# M3351 register map
File version: 1.0
Registers are 32-bit, read-write, reset 0x0 unless marked. A register's access mark holds for its fields unless they carry their own. Offsets are from the block's base; [hi:lo] are bit positions; 'fields as' and 'values as' point back to an identical list.

## CANFD0 — CANFD Register Map
Base 0x40020000
Same registers: CANFD1 0x40024000, CANFD0_NS 0x50020000, CANFD1_NS 0x50024000
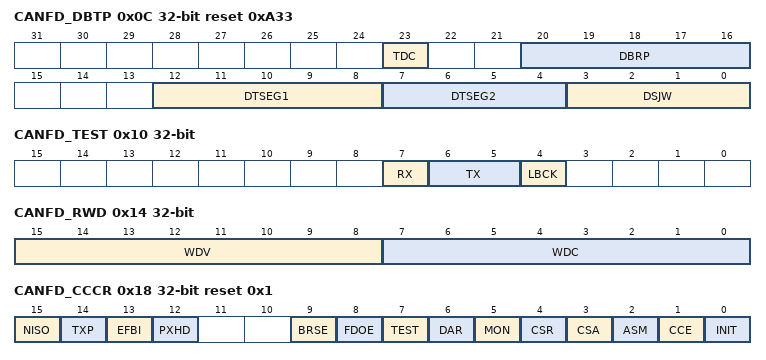
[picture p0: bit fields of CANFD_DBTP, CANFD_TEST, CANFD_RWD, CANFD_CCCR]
0x0C CANFD_DBTP reset 0xA33 — Data Bit Timing Prescaler Register (P*)
  [23] TDC — Transmitter Delay Compensation
    0=Transmitter Delay Compensation disabled; 1=Transmitter Delay Compensation enabled
  [20:16] DBRP — Data Bit Rate Prescaler
  [12:8] DTSEG1 — Data time segment before sample point
  [7:4] DTSEG2 — Data time segment after sample point
  [3:0] DSJW — Data Re-Synchronization Jump Width
0x10 CANFD_TEST — Test Register (P*)
  [7] RX — Receive Pin. Monitors the actual value of pin CANx_RXD
    0=The CAN bus is dominant (CANx_RXD = 0); 1=The CAN bus is recessive (CANx_RXD = 1)
  [6:5] TX — Control of Transmit Pin
    0=Reset value, CANx_TXD controlled by the CAN Core, updated at the end of the CAN bit time; 1=Sample Point can be monitored at pin CANx_TXD; 2=Dominant (0) level at pin CANx_TXD; 3=Recessive (1) level at pin CANx_TXD
  [4] LBCK — Loop Back Mode
    0=Reset value, Loop Back Mode disabled; 1=Loop Back Mode enabled (refer to TEST Mode in Operation Mode section)
0x14 CANFD_RWD — RAM Watchdog (P*)
  [15:8] WDV — Watchdog Value. Actual Message RAM Watchdog Counter Value.
  [7:0] WDC — Watchdog Configuration. Start value of the Message RAM Watchdog Counter. With the reset value of 00 the counter is disabled.
0x18 CANFD_CCCR reset 0x1 — CC Control Register (Pp*)
  [15] NISO — Non ISO Operation. If this bit is set, the CAN FD controller uses the CAN FD frame format as specified by the Bosch CAN FD Specification V1.0.
    0=CAN FD frame format according to ISO 11898-1:2015; 1=CAN FD frame format according to Bosch CAN FD Specification V1.0
  [14] TXP — Transmit Pause. If this bit is set, the CAN FD controller pauses for two CAN bit times before starting the next transmission after itself has successfully transmitted a frame (refer to Tx Handling section).
    0=Transmit pause disabled; 1=Transmit pause enabled
  [13] EFBI — Edge Filtering during Bus Integration
    0=Edge filtering disabled; 1=Two consecutive dominant tq required to detect an edge for hard synchronization
  [12] PXHD — Protocol Exception Handling Disable Bit. Note: When protocol exception handling is disabled, the controller will transmit an error frame when it detects a protocol exception condition.
    0=Protocol exception handling enabled; 1=Protocol exception handling disabled
  [9] BRSE — Bit Rate Switch Enable Bit
    0=Bit rate switching for transmissions disabled; 1=Bit rate switching for transmissions enabled
  [8] FDOE — FD Operation Enable Bit
    0=FD operation disabled; 1=FD operation enabled
  [7] TEST — Test Mode Enable Bit
    0=Normal operation, register TEST holds reset values; 1=Test Mode, write access to register TEST enabled
  [6] DAR — Disable Automatic Retransmission
    0=Automatic retransmission of messages not transmitted successfully enabled; 1=Automatic retransmission disabled
  [5] MON — Bus Monitoring Mode. Bit MON can only be set by the Host when both CCE and INIT are set to 1. The bit can be reset by the Host at any time.
    0=Bus Monitoring Mode disabled; 1=Bus Monitoring Mode enabled
  [4] CSR — Clock Stop Request
    0=No clock stop is requested; 1=Clock stop requested. When clock stop is requested, first INIT and then CSA will be set after all pending transfer requests have been completed and the CAN bus reached idle
  [3] CSA — Clock Stop Acknowledge
    0=No clock stop acknowledged; 1=The Controller may be set in power down by stopping AHB clock and CAN Core clock
  [2] ASM — Restricted Operation Mode. Bit ASM can only be set by the Host when both CCE and INIT are set to 1. The bit can be reset by the software at any time. This bit will be set automatically set to 1 when the Tx handler was not able to read data from the message RAM in time. For a description of the Restricted Operation Mode, refer to Restricted Operation Mode.
    0=Normal CAN operation; 1=Restricted Operation Mode active
  [1] CCE — Configuration Change Enable Bit
    0=The CPU has no write access to the protected configuration registers; 1=The CPU has write access to the protected configuration registers (while INIT (CANFD_CCCR[0]) = 1)
  [0] INIT — Initialization. Note: Due to the synchronization mechanism between the two clock domains, there may be a delay until the value written to INIT can be read back. Therefore the programmer has to assure that the previous value written to INIT has been accepted by reading INIT before setting INIT to a new value.
    0=Normal Operation; 1=Initialization is started
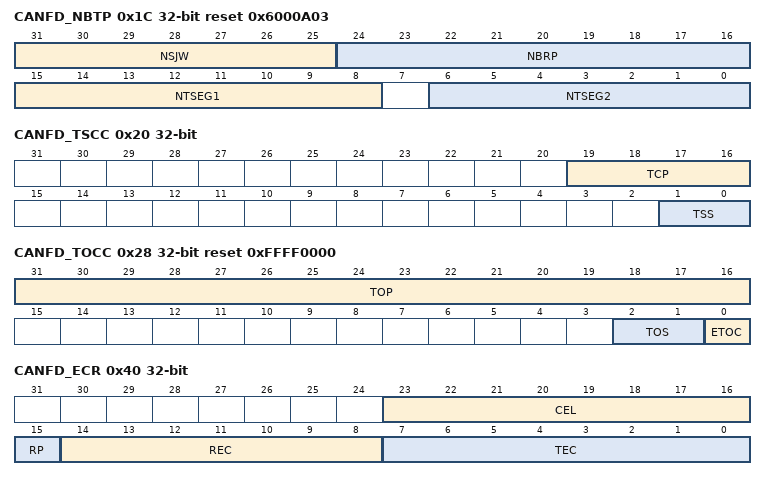
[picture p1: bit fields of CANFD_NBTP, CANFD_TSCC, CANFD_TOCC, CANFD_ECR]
0x1C CANFD_NBTP reset 0x6000A03 — Nominal Bit Timing Prescaler Register (P*)
  [31:25] NSJW — Nominal Re-Synchronization Jump Width
  [24:16] NBRP — Nominal Bit Rate Prescaler. The value by which the oscillator frequency is divided for generating the bit time quanta. The bit time is built up from a multiple of this quanta. Valid values for the Bit Rate Prescaler are 0 to 511. The actual interpretation by the hardware of this value is such that one more than the value programmed here is used
  [15:8] NTSEG1 — Nominal Time Segment before Sample Point
  [6:0] NTSEG2 — Nominal Time Segment after Sample Point. Note: With a CAN Core clock (cclk) of 8 MHz, the reset value of 0x06000A03 configures the controller for a bit rate of 500 kBit/s.
0x20 CANFD_TSCC — Timestamp Counter Configuration (P*)
  [19:16] TCP — Timestamp Counter Prescaler. Configures the timestamp and timeout counters time unit in multiples of CAN bit times [ 1...16 ]. The actual interpretation by the hardware of this value is such that one more than the value programmed here is used.
  [1:0] TSS — Timestamp Select
    0=Timestamp counter value always 0x0000; 1=Timestamp counter value incremented according to TCP; 2=2nd timestamp counter value used (clock source comes from CCLK); 3=Same as 00
0x24 CANFD_TSCV — Timestamp Counter Value (C*)
  [15:0] TSC — Timestamp Counter. Note: A wrap around is a change of the Timestamp Counter value from non-zero to 0 not caused by write access to CANFD_TSCV.
0x28 CANFD_TOCC reset 0xFFFF0000 — Timeout Counter Configuration (P*)
  [31:16] TOP — Timeout Period. Start value of the Timeout Counter (down-counter). Configures the Timeout Period.
  [2:1] TOS — Timeout Select. When operating in Continuous mode, a write to CANFD_TOCV presets the counter to the value configured by TOP (CANFD_TOCC[31:16]) and continues down-counting. When the Timeout Counter is controlled by one of the FIFOs, an empty FIFO presets the counter to the value configured by TOP (CANFD_TOCC[31:16]). Down-counting is started when the first FIFO element is stored.
    0=Continuous operation; 1=Timeout controlled by Tx Event FIFO; 2=Timeout controlled by Rx FIFO 0; 3=Timeout controlled by Rx FIFO 1
  [0] ETOC — Enable Timeout Counter. Note: For use of timeout function with CAN FD, refer to Timeout Counter section6.33.5.3.
    0=Timeout Counter disabled; 1=Timeout Counter enabled
0x2C CANFD_TOCV reset 0xFFFF — Timeout Counter Value (C*)
  [15:0] TOC — Timeout Counter. The filed is decremented in multiples of CAN bit times [ 1...16 ] depending on the configuration of TCP (CANFD_TSCC[19:16]). When decremented to 0, interrupt flag TOO (CANFD_IR[18]) is set and the timeout counter is stopped. Start and reset/restart conditions are configured via TOS (CANFD_TOCC[2:1]).
0x40 CANFD_ECR ro — Error Counter Register (X*)
  [23:16] CEL — CAN Error Logging. The counter is incremented each time when a CAN protocol error causes the 8-bit Transmit Error Counter TEC or the 7-bit Receive Error Counter REC to be incremented. The counter is also incremented when the Bus_Off limit is reached. It is not incremented when only RP is set without changing REC. The increment of CEL follows after the increment of REC or TEC. The counter is reset by read access to CEL. The counter stops at 0xFF; the next increment of TEC or REC sets interrupt flag ELO (CANFD_IR[22]).
  [15] RP — Receive Error Passive
    0=The Receive Error Counter is below the error passive level of 128; 1=The Receive Error Counter has reached the error passive level of 128
  [14:8] REC — Receive Error Counter. Actual state of the Receive Error Counter, values between 0 and 127.
  [7:0] TEC — Transmit Error Counter. Actual state of the Transmit Error Counter, values between 0 and 255. Note: When ASM (CANFD_CCCR[2]) is set, the CAN protocol controller does not increment TEC and REC when a CAN protocol error is detected, but CEL is still incremented.
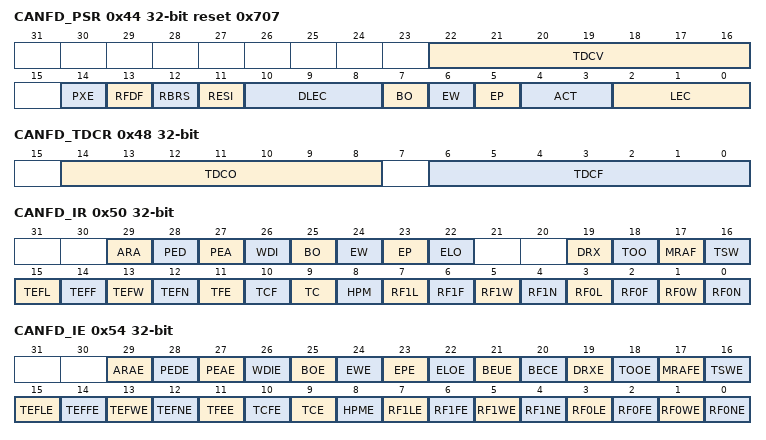
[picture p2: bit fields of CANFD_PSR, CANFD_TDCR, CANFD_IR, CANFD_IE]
0x44 CANFD_PSR ro reset 0x707 — Protocol Status Register (XS*)
  [22:16] TDCV — Transmitter Delay Compensation Value. Position of the secondary sample point, defined by the sum of the measured delay from CANx_TXD to CANx_RXD and TDCO (CANFD_TDCR[14:8]). The SSP position is, in the data phase, the number of minimum time quata (mtq) between the start of the transmitted bit and the secondary sample point. Valid values are 0 to 127 mtq.
  [14] PXE — Protocol Exception Event
    0=No protocol exception event occurred since last read access; 1=Protocol exception event occurred
  [13] RFDF — Received a CAN FD Message. This bit is set independent of acceptance filtering. Note: Byte access: Reading byte 0 will reset RFDF, reading bytes 3/2/1 has no impact.
    0=Since this bit was reset by the CPU, no CAN FD message has been received; 1=Message in CAN FD format with FDF flag set has been received
  [12] RBRS — BRS flag of last received CAN FD Message. This bit is set together with RFDF, independent of acceptance filtering. Note: Byte access: Reading byte 0 will reset RBRS, reading bytes 3/2/1 has no impact.
    0=Last received CAN FD message did not have its BRS flag set; 1=Last received CAN FD message had its BRS flag set
  [11] RESI — ESI flag of last received CAN FD Message. This bit is set together with RFDF, independent of acceptance filtering.
    0=Last received CAN FD message did not have its ESI flag set; 1=Last received CAN FD message had its ESI flag set
  [10:8] DLEC — Data Phase Last Error Code. Type of last error that occurred in the data phase of a CAN FD format frame with its BRS flag set. Coding is the same as for LEC. This field will be cleared to 0 when a CAN FD format frame with its BRS flag set has been transferred (reception or transmission) without error.
  [7] BO — Bus_Off Status
    0=The CAN FD controller is not Bus_Off; 1=The CAN FD controller is in Bus_Off state
  [6] EW — Warning Status
    0=Both error counters are below the Error_Warning limit of 96; 1=At least one of error counter has reached the Error_Warning limit of 96
  [5] EP — Error Passive
    0=The CAN FD controller is in the Error_Active state. It normally takes part in bus communication and sends an active error flag when an error has been detected; 1=The CAN FD controller is in the Error_Passive state
  [4:3] ACT — Activity. Monitors the communication state of the CAN module.
    0=Synchronizing - node is synchronizing on CAN communication; 1=Idle - node is neither receiver nor transmitter; 2=Receiver - node is operating as receiver; 3=Transmitter - node is operating as transmitter
  [2:0] LEC — Last Error Code. The LEC indicates the type of the last error to occur on the CAN bus. This field will be cleared to 0 when a message has been transferred (reception or transmission) without error.
    0=No Error: No error occurred since LEC has been reset by successful reception or transmission; 1=Stuff Error: More than 5 equal bits in a sequence have occurred in a part of a received message where this is not allowed; 2=Form Error: A fixed format part of a received frame has the wrong format; 3=AckError: The message transmitted by the CANFD CONTROLLER was not acknowledged by another node; 4=Bit1Error: During the transmission of a message (with the exception of the arbitration field), the device wanted to send a recessive level (bit of logical value 1), but the monitored bus value was dominant; 5=Bit0Error : During the transmission of a message (or acknowledge bit, or active error flag, or overload flag), the device wanted to send a dominant level (data or identifier bit logical value 0), but the monitored bus value was recessive. During Bus_Off recovery this status is set each time a sequence of 11 recessive bits has been monitored. This enables the CPU to monitor the proceeding of the Bus_Off recovery sequence (indicating the bus is not stuck at dominant or continuously disturbed); 6=CRCError: The CRC check sum of a received message was incorrect. The CRC of an incoming message does not match with the CRC calculated from the received data; 7=NoChange: Any read access to the Protocol Status Register re-initializes the LEC to 7.When the LEC shows the value 7, no CAN bus event was detected since the last CPU read access to the Protocol Status Register
0x48 CANFD_TDCR — Transmitter Delay Compensation Register (P*)
  [14:8] TDCO — Transmitter Delay Compensation SSP Offset. Offset value defining the distance between the measured delay from CANx_TXD to CANx_RXD and the secondary sample point. Valid values are 0 to 127 mtq.
  [6:0] TDCF — Transmitter Delay Compensation Filter Window Length. Defines the minimum value for the SSP position, dominant edges on CANx_RXD that would result in an earlier SSP position are ignored for transmitter delay measurement. The feature is enabled when TDCF is configured to a value greater than TDCO. Valid values are 0 to 127 mtq.
0x50 CANFD_IR — Interrupt Register
  [29] ARA — Access to Reserved Address
    0=No access to reserved address occurred; 1=Access to reserved address occurred
  [28] PED — Protocol Error in Data Phase. Note: Data bit time is used.
    0=No protocol error in data phase; 1=Protocol error in data phase detected (DLEC (CANFD_PSR[10:8]) no equal 0 or 7)
  [27] PEA — Protocol Error in Arbitration Phase. Note: Nominal bit time is used.
    0=No protocol error in arbitration phase; 1=Protocol error in arbitration phase detected (LEC (CANFD_PSR[2:0]) no equal 0 or 7)
  [26] WDI — Watchdog Interrupt
    0=No Message RAM Watchdog event occurred; 1=Message RAM Watchdog event due to missing READY
  [25] BO — Bus_Off Status
    0=Bus_Off status unchanged; 1=Bus_Off status changed
  [24] EW — Warning Status
    0=Error_Warning status unchanged; 1=Error_Warning status changed
  [23] EP — Error Passive
    0=Error_Passive status unchanged; 1=Error_Passive status changed
  [22] ELO — Error Logging Overflow
    0=CAN Error Logging Counter did not overflow; 1=Overflow of CAN Error Logging Counter occurred
  [19] DRX — Message stored to Dedicated Rx Buffer. The flag is set whenever a received message has been stored into a dedicated Rx Buffer.
    0=No Rx Buffer updated; 1=At least one received message stored into an Rx Buffer
  [18] TOO — Timeout Occurred
    0=No timeout; 1=Timeout reached
  [17] MRAF — Message RAM Access Failure. The flag is set, when the Rx Handler - Has not completed acceptance filtering or storage of an accepted message until the arbitration field of the following message has been received. In this case acceptance filtering or message storage is aborted and the Rx Handler starts processing of the following message. - Was not able to write a message to the Message RAM. In this case message storage is aborted. In both cases the FIFO put index is not updated resp. the New Data flag for a dedicated Rx Buffer is not set, a partly stored message is overwritten when the next message is stored to this location. The flag is also set when the Tx Handler was not able to read a message from the Message RAM in time. In this case message transmission is aborted. In case of a Tx Handler access failure the CAN FD controller is switched into Restricted Operation Mode (refer to Restricted Operation Mode). To leave Restricted Operation Mode, the Host CPU has to reset ASM (CANFD_CCCR[2]).
    0=No Message RAM access failure occurred; 1=Message RAM access failure occurred
  [16] TSW — Timestamp Wraparound
    0=No timestamp counter wrap-around; 1=Timestamp counter wrapped around
  [15] TEFL — Tx Event FIFO Element Lost
    0=No Tx Event FIFO element lost; 1=Tx Event FIFO element lost, also set after write attempt to Tx Event FIFO of size zero
  [14] TEFF — Tx Event FIFO Full
    0=Tx Event FIFO not full; 1=Tx Event FIFO full
  [13] TEFW — Tx Event FIFO Watermark Reached
    0=Tx Event FIFO fill level below watermark; 1=Tx Event FIFO fill level reached watermark
  [12] TEFN — Tx Event FIFO New Entry
    0=Tx Event FIFO unchanged; 1=Tx Handler wrote Tx Event FIFO element
  [11] TFE — Tx FIFO Empty
    0=Tx FIFO non-empty; 1=Tx FIFO empty
  [10] TCF — Transmission Cancellation Finished
    0=No transmission cancellation finished; 1=Transmission cancellation finished
  [9] TC — Transmission Completed
    0=No transmission completed; 1=Transmission completed
  [8] HPM — High Priority Message
    0=No high priority message received; 1=High priority message received
  [7] RF1L — Rx FIFO 1 Message Lost
    0=No Rx FIFO 1 message lost; 1=Rx FIFO 1 message lost, also set after write attempt to Rx FIFO 1 of size zero
  [6] RF1F — Rx FIFO 1 Full
    0=Rx FIFO 1 not full; 1=Rx FIFO 1 full
  [5] RF1W — Rx FIFO 1 Watermark Reached
    0=Rx FIFO 1 fill level below watermark; 1=Rx FIFO 1 fill level reached watermark
  [4] RF1N — Rx FIFO 1 New Message
    0=No new message written to Rx FIFO 1; 1=New message written to Rx FIFO 1
  [3] RF0L — Rx FIFO 0 Message Lost
    0=No Rx FIFO 0 message lost; 1=Rx FIFO 0 message lost, also set after write attempt to Rx FIFO 0 of size zero
  [2] RF0F — Rx FIFO 0 Full
    0=Rx FIFO 0 not full; 1=Rx FIFO 0 full
  [1] RF0W — Rx FIFO 0 Watermark Reached
    0=Rx FIFO 0 fill level below watermark; 1=Rx FIFO 0 fill level reached watermark
  [0] RF0N — Rx FIFO 0 New Message
    0=No new message written to Rx FIFO 0; 1=New message written to Rx FIFO 0
0x54 CANFD_IE — Interrupt Enable
  [all] fields
    0=Interrupt disabled; 1=Interrupt enabled
  [29] ARAE — Access to Reserved Address Enable Bit
  [28] PEDE — Protocol Error in Data Phase Enable Bit
  [27] PEAE — Protocol Error in Arbitration Phase Enable Bit
  [26] WDIE — Watchdog Interrupt Enable Bit
  [25] BOE — Bus_Off Status Interrupt Enable Bit
  [24] EWE — Warning Status Interrupt Enable Bit
  [23] EPE — Error Passive Interrupt Enable Bit
  [22] ELOE — Error Logging Overflow Interrupt Enable Bit
  [21] BEUE — Bit Error Uncorrected Interrupt Enable Bit
  [20] BECE — Bit Error Corrected Interrupt Enable Bit
  [19] DRXE — Message stored to Dedicated Rx Buffer Interrupt Enable Bit
  [18] TOOE — Timeout Occurred Interrupt Enable Bit
  [17] MRAFE — Message RAM Access Failure Interrupt Enable Bit
  [16] TSWE — Timestamp Wraparound Interrupt Enable Bit
  [15] TEFLE — Tx Event FIFO Event Lost Interrupt Enable Bit
  [14] TEFFE — Tx Event FIFO Full Interrupt Enable Bit
  [13] TEFWE — Tx Event FIFO Watermark Reached Interrupt Enable Bit
  [12] TEFNE — Tx Event FIFO New Entry Interrupt Enable Bit
  [11] TFEE — Tx FIFO Empty Interrupt Enable Bit
  [10] TCFE — Transmission Cancellation Finished Interrupt Enable Bit
  [9] TCE — Transmission Completed Interrupt Enable Bit
  [8] HPME — High Priority Message Interrupt Enable Bit
  [7] RF1LE — Rx FIFO 1 Message Lost Interrupt Enable Bit
  [6] RF1FE — Rx FIFO 1 Full Interrupt Enable Bit
  [5] RF1WE — Rx FIFO 1 Watermark Reached Interrupt Enable Bit
  [4] RF1NE — Rx FIFO 1 New Message Interrupt Enable Bit
  [3] RF0LE — Rx FIFO 0 Message Lost Interrupt Enable Bit
  [2] RF0FE — Rx FIFO 0 Full Interrupt Enable Bit
  [1] RF0WE — Rx FIFO 0 Watermark Reached Interrupt Enable Bit
  [0] RF0NE — Rx FIFO 0 New Message Interrupt Enable Bit
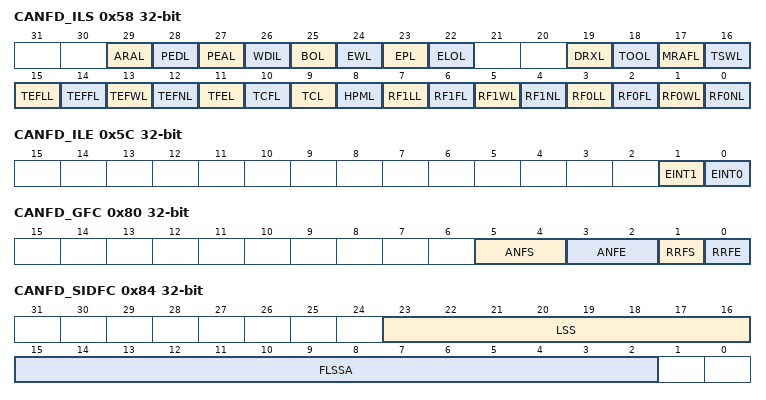
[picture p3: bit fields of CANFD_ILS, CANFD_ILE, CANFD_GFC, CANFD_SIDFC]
0x58 CANFD_ILS — Interrupt Line Select
  [all] fields
    0=Interrupt assigned to CAN interrupt line 0; 1=Interrupt assigned to CAN interrupt line 1
  [29] ARAL — Access to Reserved Address Line
  [28] PEDL — Protocol Error in Data Phase Line
  [27] PEAL — Protocol Error in Arbitration Phase Line
  [26] WDIL — Watchdog Interrupt Line
  [25] BOL — Bus_Off Status Interrupt Line
  [24] EWL — Warning Status Interrupt Line
  [23] EPL — Error Passive Interrupt Line
  [22] ELOL — Error Logging Overflow Interrupt Line
  [19] DRXL — Message stored to Dedicated Rx Buffer Interrupt Line
  [18] TOOL — Timeout Occurred Interrupt Line
  [17] MRAFL — Message RAM Access Failure Interrupt Line
  [16] TSWL — Timestamp Wraparound Interrupt Line
  [15] TEFLL — Tx Event FIFO Event Lost Interrupt Line
  [14] TEFFL — Tx Event FIFO Full Interrupt Line
  [13] TEFWL — Tx Event FIFO Watermark Reached Interrupt Line
  [12] TEFNL — Tx Event FIFO New Entry Interrupt Line
  [11] TFEL — Tx FIFO Empty Interrupt Line
  [10] TCFL — Transmission Cancellation Finished Interrupt Line
  [9] TCL — Transmission Completed Interrupt Line
  [8] HPML — High Priority Message Interrupt Line
  [7] RF1LL — Rx FIFO 1 Message Lost Interrupt Line
  [6] RF1FL — Rx FIFO 1 Full Interrupt Line
  [5] RF1WL — Rx FIFO 1 Watermark Reached Interrupt Line
  [4] RF1NL — Rx FIFO 1 New Message Interrupt Line
  [3] RF0LL — Rx FIFO 0 Message Lost Interrupt Line
  [2] RF0FL — Rx FIFO 0 Full Interrupt Line
  [1] RF0WL — Rx FIFO 0 Watermark Reached Interrupt Line
  [0] RF0NL — Rx FIFO 0 New Message Interrupt Line
0x5C CANFD_ILE — Interrupt Line Enable
  [1] EINT1 — Enable Interrupt Line 1
    0=Interrupt line canfd_int1 disabled; 1=Interrupt line canfd_int1 enabled
  [0] EINT0 — Enable Interrupt Line 0
    0=Interrupt line canfd_int0 disabled; 1=Interrupt line canfd_int0 enabled
0x80 CANFD_GFC — Global Filter Configuration (P*)
  [5:4] ANFS — Accept Non-matching Frames Standard. Defines how received messages with 11-bit IDs that do not match any element of the filter list are treated.
    0=Accept in Rx FIFO 0; 1=Accept in Rx FIFO 1; 2=Reject; 3=Reject
  [3:2] ANFE — Accept Non-matching Frames Extended. Defines how received messages with 29-bit IDs that do not match any element of the filter list are treated.
    values as ANFS
  [1] RRFS — Reject Remote Frames Standard
    0=Filter remote frames with 11-bit standard IDs; 1=Reject all remote frames with 11-bit standard IDs
  [0] RRFE — Reject Remote Frames Extended
    0=Filter remote frames with 29-bit extended IDs; 1=Reject all remote frames with 29-bit extended IDs
0x84 CANFD_SIDFC — Standard ID Filter Configuration (P*)
  [23:16] LSS — List Size Standard
    0=No standard Message ID filter
  [15:2] FLSSA — Filter List Standard Start Address. Start address of standard Message ID filter list (32-bit word address, refer to Figure 6.3311).
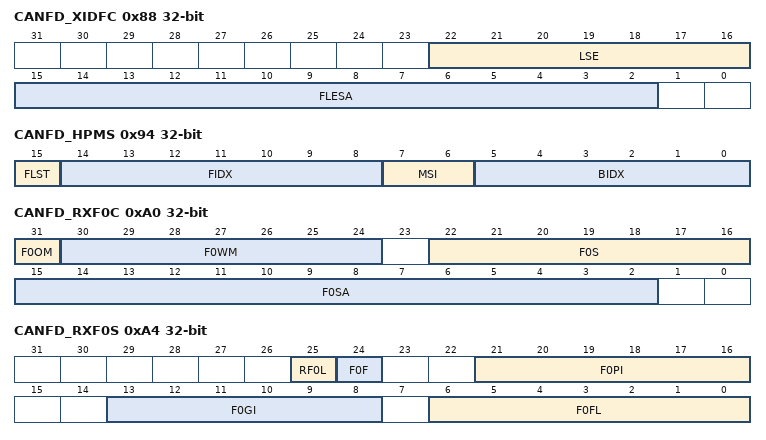
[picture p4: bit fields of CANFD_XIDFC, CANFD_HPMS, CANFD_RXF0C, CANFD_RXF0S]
0x88 CANFD_XIDFC — Extended ID Filter Configuration (P*)
  [22:16] LSE — List Size Extended
    0=No extended Message ID filter
  [15:2] FLESA — Filter List Extended Start Address. Start address of extended Message ID filter list (32-bit word address, refer to Figure 6.3311).
0x90 CANFD_XIDAM reset 0x1FFFFFFF — Extended ID AND Mask (P*)
  [28:0] EIDM — Extended ID Mask. For acceptance filtering of extended frames, the Extended ID AND Mask is ANDed with the Message ID of a received frame. Intended for masking of 29-bit IDs in SAE J1939. With the reset value of all bits set to one the mask is not active.
0x94 CANFD_HPMS ro — High Priority Message Status
  [15] FLST — Filter List. Indicates the filter list of the matching filter element.
    0=Standard Filter List; 1=Extended Filter List
  [14:8] FIDX — Filter Index. Index of matching filter element. Range is 0 to LSS (CANFD_SIDFC[23:16]) - 1 or LSE (CANFD_XIDFC[22:16]) - 1
  [7:6] MSI — Message Storage Indicator
    0=No FIFO selected; 1=FIFO message lost; 2=Message stored in FIFO 0; 3=Message stored in FIFO 1
  [5:0] BIDX — Buffer Index
0x98 CANFD_NDAT1 — New Data 1
  [31:0] NDn — New Data. The register holds the New Data flags of Rx Buffers 0 to 31. The flags are set when the respective Rx Buffer has been updated from a received frame. The flags remain set until the Host clears them. A flag is cleared by writing a 1 to the corresponding bit position. Writing a 0 has no effect. A hard reset will clear the register.
    0=Rx Buffer not updated; 1=Rx Buffer updated from new message
0x9C CANFD_NDAT2 — New Data 2
  [31:0] NDn — New Data. The register holds the New Data flags of Rx Buffers 32 to 63. The flags are set when the respective Rx Buffer has been updated from a received frame. The flags remain set until the Host clears them. A flag is cleared by writing a 1 to the corresponding bit position. Writing a 0 has no effect. A hard reset will clear the register.
    values as CANFD_NDAT1.NDn
0xA0 CANFD_RXF0C — Rx FIFO 0 Configuration (P*)
  [31] F0OM — FIFO 0 Operation Mode. FIFO 0 can be operated in blocking or in overwrite mode (refer to Rx FIFOs).
    0=FIFO 0 blocking mode; 1=FIFO 0 overwrite mode
  [30:24] F0WM — Rx FIFO 0 Watermark
    0=Watermark interrupt disabled
  [22:16] F0S — Rx FIFO 0 Size. The Rx FIFO 0 elements are indexed from 0 to F0S - 1
    0=No Rx FIFO 0
  [15:2] F0SA — Rx FIFO 0 Start Address. Start address of Rx FIFO 0 in Message RAM (32-bit word address).
0xA4 CANFD_RXF0S ro — Rx FIFO 0 Status
  [25] RF0L — Rx FIFO 0 Message Lost
    1=Rx FIFO 0 message lost, also set after write attempt to Rx FIFO 0 of size zero
  [24] F0F — Rx FIFO 0 Full
    0=Rx FIFO 0 not full; 1=Rx FIFO 0 full
  [21:16] F0PI — Rx FIFO 0 Put Index. Rx FIFO 0 write index pointer, range 0 to 63.
  [13:8] F0GI — Rx FIFO 0 Get Index. Rx FIFO 0 read index pointer, range 0 to 63.
  [6:0] F0FL — Rx FIFO 0 Fill Level. Number of elements stored in Rx FIFO 0, range 0 to 64
0xA8 CANFD_RXF0A — Rx FIFO 0 Acknowledge
  [5:0] F0AI — Rx FIFO 0 Acknowledge Index. After the Host has read a message or a sequence of messages from Rx FIFO 0 it has to write the buffer index of the last element read from Rx FIFO 0 to F0AI. This will set the Rx FIFO 0 Get Index F0GI (CANFD_RXF0S[13:8]) to F0AI (CANFD_RXF0A[5:0]) + 1 and update the FIFO 0 Fill Level F0FL (CANFD_RXF0S[6:0]).
0xAC CANFD_RXBC — Rx Buffer Configuration (P*)
  [15:2] RBSA — Rx Buffer Start Address. Configures the start address of the Rx Buffers section in the Message RAM (32-bit word address).
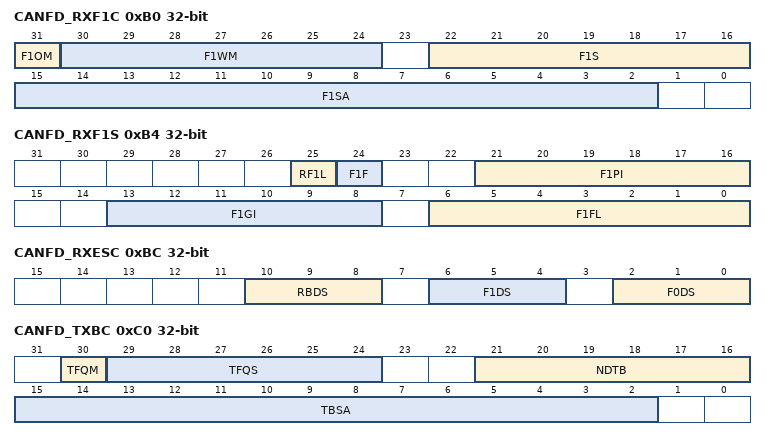
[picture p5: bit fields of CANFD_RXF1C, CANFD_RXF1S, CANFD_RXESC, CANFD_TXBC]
0xB0 CANFD_RXF1C — Rx FIFO 1 Configuration (P*)
  [31] F1OM — FIFO 1 Operation Mode. FIFO 1 can be operated in blocking or in overwrite mode (refer to Rx FIFOs).
    0=FIFO 1 blocking mode; 1=FIFO 1 overwrite mode
  [30:24] F1WM — Rx FIFO 1 Watermark
    0=Watermark interrupt disabled
  [22:16] F1S — Rx FIFO 1 Size. The Rx FIFO 1 elements are indexed from 0 to F1S - 1
    0=No Rx FIFO 1
  [15:2] F1SA — Rx FIFO 1 Start Address. Start address of Rx FIFO 1 in Message RAM (32-bit word address, refer to Figure 6.3311).
0xB4 CANFD_RXF1S ro — Rx FIFO 1 Status
  [25] RF1L — Rx FIFO 1 Message Lost
    1=Rx FIFO 1 message lost, also set after write attempt to Rx FIFO 1 of size zero
  [24] F1F — Rx FIFO 1 Full
    0=Rx FIFO 1 not full; 1=Rx FIFO 1 full
  [21:16] F1PI — Rx FIFO 1 Put Index. Rx FIFO 1 write index pointer, range 0 to 63.
  [13:8] F1GI — Rx FIFO 1 Get Index. Rx FIFO 1 read index pointer, range 0 to 63.
  [6:0] F1FL — Rx FIFO 1 Fill Level. Number of elements stored in Rx FIFO 1, range 0 to 64
0xB8 CANFD_RXF1A — Rx FIFO 1 Acknowledge
  [5:0] F1AI — Rx FIFO 1 Acknowledge Index. After the Host has read a message or a sequence of messages from Rx FIFO 1 it has to write the buffer index of the last element read from Rx FIFO 1 to F1AI. This will set the Rx FIFO 1 Get Index F1GI (CANFD_RXF1S[13:8]) to F1AI (CANFD_RXF1A[5:0]) + 1 and update the FIFO 1 Fill Level F1FL (CANFD_RXF1S[6:0]).
0xBC CANFD_RXESC — Rx Buffer / FIFO Element Size Configuration (P*)
  [all] fields
    0=8 byte data field; 1=12 byte data field; 2=16 byte data field; 3=20 byte data field; 4=24 byte data field; 5=32 byte data field; 6=48 byte data field; 7=64 byte data field
  [10:8] RBDS — Rx Buffer Data Field Size
  [6:4] F1DS — Rx FIFO 1 Data Field Size
  [2:0] F0DS — Rx FIFO 0 Data Field Size. Note: In case the data field size of an accepted CAN frame exceeds the data field size configured for the matching Rx Buffer or Rx FIFO, only the number of bytes as configured by CANFD_RXESC are stored to the Rx Buffer resp. Rx FIFO element. The rest of the frame data field is ignored.
0xC0 CANFD_TXBC — Tx Buffer Configuration (P*)
  [30] TFQM — Tx FIFO/Queue Mode
    0=Tx FIFO operation; 1=Tx Queue operation
  [29:24] TFQS — Transmit FIFO/Queue Size
    0=No Tx FIFO/Queue
  [21:16] NDTB — Number of Dedicated Transmit Buffers
    0=No Dedicated Tx Buffers
  [15:2] TBSA — Tx Buffers Start Address. Start address of Tx Buffers section in Message RAM (32-bit word address, refer to Figure 6.3311). Note: The sum of TFQS and NDTB may be not greater than 32. There is no check for erroneous configurations. The Tx Buffers section in the Message RAM starts with the dedicated Tx Buffers.
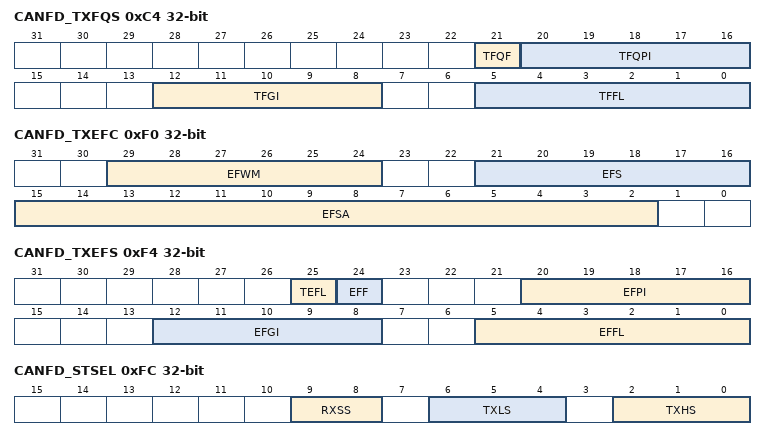
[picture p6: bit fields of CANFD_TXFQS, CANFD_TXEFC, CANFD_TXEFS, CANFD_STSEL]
0xC4 CANFD_TXFQS ro — Tx FIFO/Queue Status
  [21] TFQF — Tx FIFO/Queue Full
    0=Tx FIFO/Queue not full; 1=Tx FIFO/Queue full
  [20:16] TFQPI — Tx FIFO/Queue Put Index. Tx FIFO/Queue write index pointer, range 0 to 31.
  [12:8] TFGI — Tx FIFO Get Index
  [5:0] TFFL — Tx FIFO Free Level. Note: In case of mixed configurations where dedicated Tx Buffers are combined with a Tx FIFO or a Tx Queue, the Put and Get Indices indicate the number of the Tx Buffer starting with the first dedicated Tx Buffers. Example: For a configuration of 12 dedicated Tx Buffers and a Tx FIFO of 20 Buffers a Put Index of 15 points to the fourth buffer of the Tx FIFO.
0xC8 CANFD_TXESC — Tx Buffer Element Size Configuration (P*)
  [2:0] TBDS — Tx Buffer Data Field Size. Note: In case the data length code DLC of a Tx Buffer element is configured to a value higher than the Tx Buffer data field size TBDS (CANFD_TXESC[2:0]), the bytes not defined by the Tx Buffer are transmitted as 0xCC (padding bytes).
    values as the fields of CANFD_RXESC
0xCC CANFD_TXBRP ro — Tx Buffer Request Pending
  [31:0] TRPn — Transmission Request PendingEach Tx Buffer has its own Transmission Request Pending bit The bits are set via register CANFD_TXBAR The bits are reset after a requested transmission has completed or has been cancelled via register CANFD_TXBCR. CANFD_TXBRP bits are set only for those Tx Buffers configured via CANFD_TXBC. After a CANFD_TXBRP bit has been set, a Tx scan (refer to section 6.33.5.5, Tx Handling) is started to check for the pending Tx request with the highest priority (Tx Buffer with lowest Message ID). A cancellation request resets the corresponding transmission request pending bit of register CANFD_TXBRP. In case a transmission has already been started when a cancellation is requested, this is done at the end of the transmission, regardless whether the transmission was successful or not. The cancellation request bits are reset directly after the corresponding CANFD_TXBRP bit has been reset. After a cancellation has been requested, a finished cancellation is signaled via CANFD_TXBCF. - after successful transmission together with the corresponding CANFD_TXBTO bit - when the transmission has not yet been started at the point of cancellation - when the transmission has been aborted due to lost arbitration - when an error occurred during frame transmission. In DAR mode all transmissions are automatically cancelled if they are not successful. The corresponding CANFD_TXBCF bit is set for all unsuccessful transmissions. Note: CANFD_TXBRP bits which are set while a Tx scan is in progress are not considered during this particular Tx scan. In case a cancellation is requested for such a Tx Buffer, this Add Request is cancelled immediately, the corresponding CANFD_TXBRP bit is reset.
    0=No transmission request pending; 1=Transmission request pending
0xD0 CANFD_TXBAR — Tx Buffer Add Request
  [31:0] ARn — Add RequestEach Tx Buffer has its own Add Request bit Writing a 1 will set the corresponding Add Request bit; writing a 0 has no impact This enables the Host to set transmission requests for multiple Tx Buffers with one write to CANFD_TXBAR CANFD_TXBAR bits are set only for those Tx Buffers configured via CANFD_TXBC When no Tx scan is running, the bits are reset immediately, else the bits remain set until the Tx scan process has completed. Note: If an add request is applied for a Tx Buffer with pending transmission request (corresponding CANFD_TXBRP bit already set), this add request is ignored.
    0=No transmission request added; 1=Transmission requested added
0xD4 CANFD_TXBCR — Tx Buffer Cancellation Request
  [31:0] CRn — Cancellation Request. Each Tx Buffer has its own Cancellation Request bit. Writing a 1 will set the corresponding Cancellation Request bit; writing a 0 has no impact. This enables the Host to set cancellation requests for multiple Tx Buffers with one write to CANFD_TXBCR. CANFD_TXBCR bits are set only for those Tx Buffers configured via CANFD_TXBC. The bits remain set until the corresponding bit of CANFD_TXBRP is reset.
    0=No cancellation pending; 1=Cancellation pending
0xD8 CANFD_TXBTO ro — Tx Buffer Transmission Occurred
  [31:0] TOn — Transmission Occurred. Each Tx Buffer has its own Transmission Occurred bit. The bits are set when the corresponding CANFD_TXBRP bit is cleared after a successful transmission. The bits are reset when a new transmission is requested by writing a 1 to the corresponding bit of register CANFD_TXBAR.
    0=No transmission occurred; 1=Transmission occurred
0xDC CANFD_TXBCF ro — Tx Buffer Cancellation Finished
  [31:0] CFn — Cancellation Finished. Each Tx Buffer has its own Cancellation Finished bit. The bits are set when the corresponding CANFD_TXBRP bit is cleared after a cancellation was requested via CANFD_TXBCR. In case the corresponding CANFD_TXBRP bit was not set at the point of cancellation, CF is set immediately. The bits are reset when a new transmission is requested by writing a 1 to the corresponding bit of register CANFD_TXBAR.
    0=No transmit buffer cancellation; 1=Transmit buffer cancellation finished
0xE0 CANFD_TXBTIE — Tx Buffer Transmission Interrupt Enable
  [31:0] TIEn — Transmission Interrupt Enable Bits. Each Tx Buffer has its own Transmission Interrupt Enable bit.
    0=Transmission interrupt disabled; 1=Transmission interrupt enabled
0xE4 CANFD_TXBCIE — Tx Buffer Cancellation Finished Interrupt Enable
  [31:0] CFIEn — Cancellation Finished Interrupt Enable Bits. Each Tx Buffer has its own Cancellation Finished Interrupt Enable bit.
    0=Cancellation finished interrupt disabled; 1=Cancellation finished interrupt enabled
0xF0 CANFD_TXEFC — Tx Event FIFO Configuration (P*)
  [29:24] EFWM — Event FIFO Watermark
    0=Watermark interrupt disabled
  [21:16] EFS — Event FIFO Size. The Tx Event FIFO elements are indexed from 0 to EFS - 1
    0=Tx Event FIFO disabled
  [15:2] EFSA — Event FIFO Start Address. Start address of Tx Event FIFO in Message RAM (32-bit word address, refer to Figure 6.3311).
0xF4 CANFD_TXEFS ro — Tx Event FIFO Status
  [25] TEFL — Tx Event FIFO Element Lost. This bit is a copy of interrupt flag TEFL (CANFD_IR[15]). When TEFL is reset, this bit is also reset.
    values as CANFD_IR.TEFL
  [24] EFF — Event FIFO Full
    0=Tx Event FIFO not full; 1=Tx Event FIFO full
  [20:16] EFPI — Event FIFO Put Index. Tx Event FIFO write index pointer, range 0 to 31
  [12:8] EFGI — Event FIFO Get Index. Tx Event FIFO read index pointer, range 0 to 31
  [5:0] EFFL — Event FIFO Fill Level. Number of elements stored in Tx Event FIFO, range 0 to 32
0xF8 CANFD_TXEFA — Tx Event FIFO Acknowledge
  [4:0] EFAI — Event FIFO Acknowledge Index. After the Host has read an element or a sequence of elements from the Tx Event FIFO it has to write the index of the last element read from Tx Event FIFO to EFAI. This will set the Tx Event FIFO Get Index EFGI (CANFD_TXEFS[12:8]) to EFAI + 1 and update the Event FIFO Fill Level EFFL (CANFD_TXEFS[5:0])
0xFC CANFD_STSEL — Tx Rx Signal Type Selection Register
  [9:8] RXSS — CAN Rx Signal Selection
    0=from CAN_Rx pin; 1=from ACMP0 output; 2=from ACMP1 output
  [6:4] TXLS — CAN TxL Signal Type. Based on CAN_Tx signal, the CAN_TxL will follow below table to change.
    0=CAN_TxL Logic 0 will output low, CAN_TxL Logic 1 will output high; 1=CAN_TxL Logic 0 will output high, CAN_TxL Logic 1 will output low; 2=CAN_TxL Logic 0 will output low, CAN_TxL Logic 1 will be floating; 3=CAN_TxL Logic 0 will be floating, CAN_TxL Logic 1 will output low; 4=CAN_TxL Logic 0 will output high, CAN_TxL Logic 1 will be floating; 5=CAN_TxL Logic 0 will be floating, CAN_TxL Logic 1 will output high
  [2:0] TXHS — CAN TxH Signal Type. Based on CAN_Tx signal, the CAN_TxH will follow below table to change.
    0=CAN_TxH Logic 0 will output low, CAN_TxH Logic 1 will output high; 1=CAN_TxH Logic 0 will output high, CAN_TxH Logic 1 will output low; 2=CAN_TxH Logic 0 will output low, CAN_TxH Logic 1 will be floating; 3=CAN_TxH Logic 0 will be floating, CAN_TxH Logic 1 will output low; 4=CAN_TxH Logic 0 will output high, CAN_TxH Logic 1 will be floating
